# ioam3358 register map
Registers are 32-bit, access not given, no defined reset value unless marked. A register's access mark holds for its fields unless they carry their own. Addresses are absolute; registers are grouped by the start of their names; [hi:lo] are bit positions; {n}, {i} and the like mark numbered series.

## SPINLOCK
0x480CA000 SPINLOCK_REV
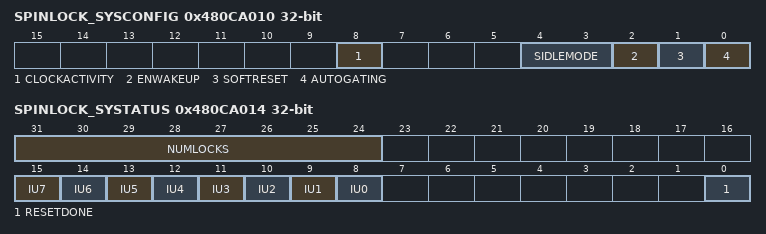
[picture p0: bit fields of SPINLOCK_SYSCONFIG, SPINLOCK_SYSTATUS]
0x480CA010 SPINLOCK_SYSCONFIG
  [8] CLOCKACTIVITY, [4:3] SIDLEMODE, [2] ENWAKEUP, [1] SOFTRESET, [0] AUTOGATING
0x480CA014 SPINLOCK_SYSTATUS
  [31:24] NUMLOCKS, [n+8] IU{n} (n=0..7), [0] RESETDONE
{0x480CA800+4i} SPINLOCK_LOCK_REG_{i} (i=0..31)
  [0] TAKEN

## MMCHS0
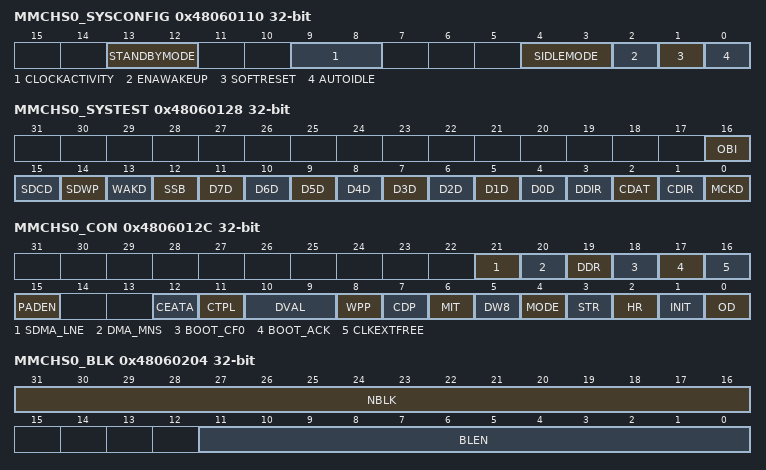
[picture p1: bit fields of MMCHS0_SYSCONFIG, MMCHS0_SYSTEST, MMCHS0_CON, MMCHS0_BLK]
0x48060110 MMCHS0_SYSCONFIG
  [13:12] STANDBYMODE, [9:8] CLOCKACTIVITY, [4:3] SIDLEMODE, [2] ENAWAKEUP, [1] SOFTRESET, [0] AUTOIDLE
0x48060114 MMCHS0_SYSSTATUS
  [0] RESETDONE
0x48060124 MMCHS0_CSRE
0x48060128 MMCHS0_SYSTEST
  [16] OBI, [15] SDCD, [14] SDWP, [13] WAKD, [12] SSB, [n+4] D{n}D (n=0..7), [3] DDIR, [2] CDAT, [1] CDIR, [0] MCKD
0x4806012C MMCHS0_CON
  [21] SDMA_LNE, [20] DMA_MNS, [19] DDR, [18] BOOT_CF0, [17] BOOT_ACK, [16] CLKEXTFREE, [15] PADEN, [12] CEATA, [11] CTPL, [10:9] DVAL, [8] WPP, [7] CDP, [6] MIT, [5] DW8, [4] MODE, [3] STR, [2] HR, [1] INIT, [0] OD
0x48060130 MMCHS0_PWCNT
  [15:0] PWRCNT
0x48060200 MMCHS0_SDMASA
0x48060204 MMCHS0_BLK
  [31:16] NBLK, [11:0] BLEN
0x48060208 MMCHS0_ARG
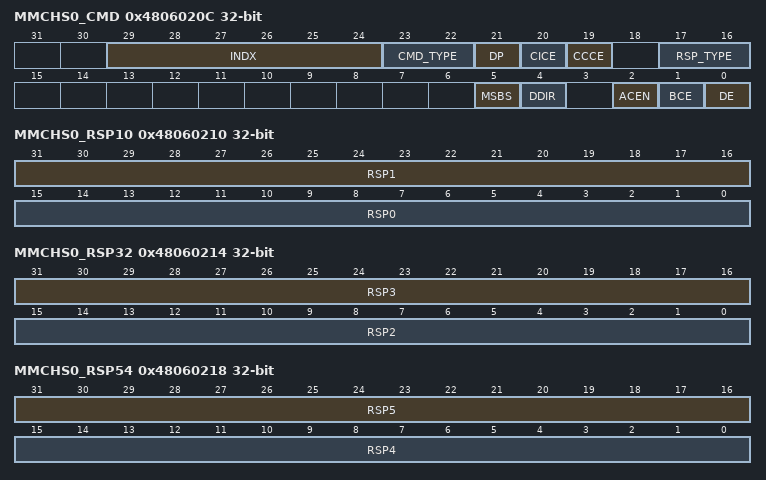
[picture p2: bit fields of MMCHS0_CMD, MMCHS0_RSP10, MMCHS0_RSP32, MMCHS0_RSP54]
0x4806020C MMCHS0_CMD
  [29:24] INDX, [23:22] CMD_TYPE, [21] DP, [20] CICE, [19] CCCE, [17:16] RSP_TYPE, [5] MSBS, [4] DDIR, [2] ACEN, [1] BCE, [0] DE
0x48060210 MMCHS0_RSP10
  [31:16] RSP1, [15:0] RSP0
0x48060214 MMCHS0_RSP32
  [31:16] RSP3, [15:0] RSP2
0x48060218 MMCHS0_RSP54
  [31:16] RSP5, [15:0] RSP4
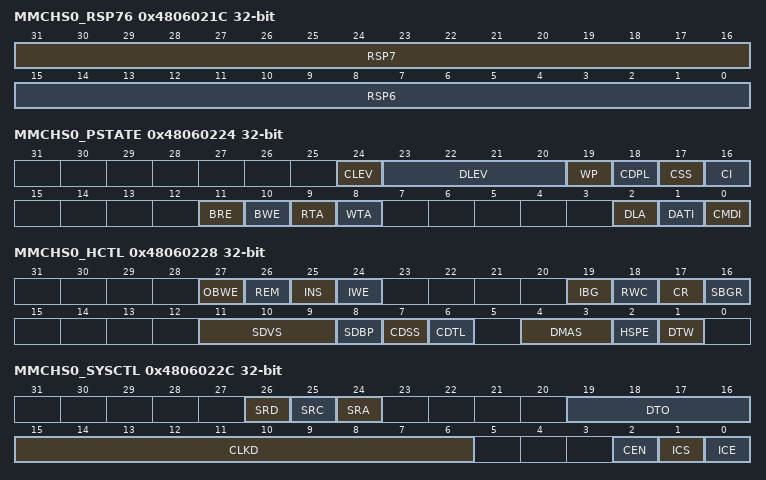
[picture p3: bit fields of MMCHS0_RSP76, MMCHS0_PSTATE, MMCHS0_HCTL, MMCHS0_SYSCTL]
0x4806021C MMCHS0_RSP76
  [31:16] RSP7, [15:0] RSP6
0x48060220 MMCHS0_DATA
0x48060224 MMCHS0_PSTATE
  [24] CLEV, [23:20] DLEV, [19] WP, [18] CDPL, [17] CSS, [16] CI, [11] BRE, [10] BWE, [9] RTA, [8] WTA, [2] DLA, [1] DATI, [0] CMDI
0x48060228 MMCHS0_HCTL
  [27] OBWE, [26] REM, [25] INS, [24] IWE, [19] IBG, [18] RWC, [17] CR, [16] SBGR, [11:9] SDVS, [8] SDBP, [7] CDSS, [6] CDTL, [4:3] DMAS, [2] HSPE, [1] DTW
0x4806022C MMCHS0_SYSCTL
  [26] SRD, [25] SRC, [24] SRA, [19:16] DTO, [15:6] CLKD, [2] CEN, [1] ICS, [0] ICE
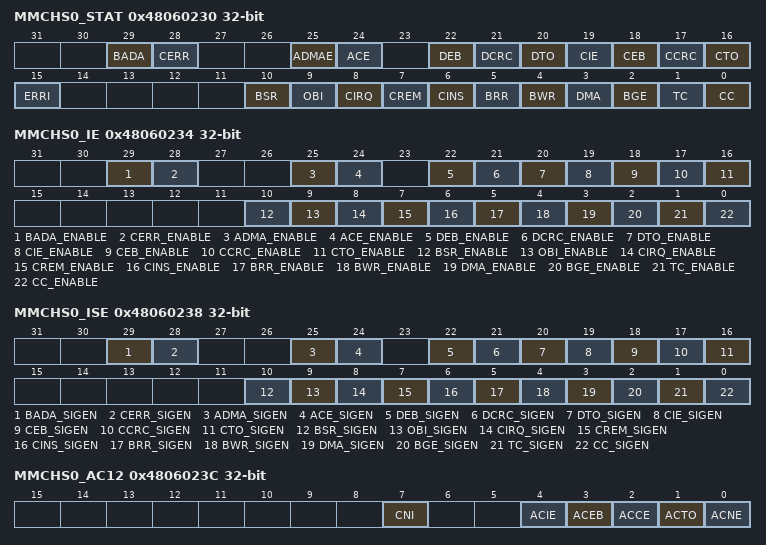
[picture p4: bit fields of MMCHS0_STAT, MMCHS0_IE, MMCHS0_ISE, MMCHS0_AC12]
0x48060230 MMCHS0_STAT
  [29] BADA, [28] CERR, [25] ADMAE, [24] ACE, [22] DEB, [21] DCRC, [20] DTO, [19] CIE, [18] CEB, [17] CCRC, [16] CTO, [15] ERRI, [10] BSR, [9] OBI, [8] CIRQ, [7] CREM, [6] CINS, [5] BRR, [4] BWR, [3] DMA, [2] BGE, [1] TC, [0] CC
0x48060234 MMCHS0_IE
  [29] BADA_ENABLE, [28] CERR_ENABLE, [25] ADMA_ENABLE, [24] ACE_ENABLE, [22] DEB_ENABLE, [21] DCRC_ENABLE, [20] DTO_ENABLE, [19] CIE_ENABLE, [18] CEB_ENABLE, [17] CCRC_ENABLE, [16] CTO_ENABLE, [10] BSR_ENABLE, [9] OBI_ENABLE, [8] CIRQ_ENABLE, [7] CREM_ENABLE, [6] CINS_ENABLE, [5] BRR_ENABLE, [4] BWR_ENABLE, [3] DMA_ENABLE, [2] BGE_ENABLE, [1] TC_ENABLE, [0] CC_ENABLE
0x48060238 MMCHS0_ISE
  [29] BADA_SIGEN, [28] CERR_SIGEN, [25] ADMA_SIGEN, [24] ACE_SIGEN, [22] DEB_SIGEN, [21] DCRC_SIGEN, [20] DTO_SIGEN, [19] CIE_SIGEN, [18] CEB_SIGEN, [17] CCRC_SIGEN, [16] CTO_SIGEN, [10] BSR_SIGEN, [9] OBI_SIGEN, [8] CIRQ_SIGEN, [7] CREM_SIGEN, [6] CINS_SIGEN, [5] BRR_SIGEN, [4] BWR_SIGEN, [3] DMA_SIGEN, [2] BGE_SIGEN, [1] TC_SIGEN, [0] CC_SIGEN
0x4806023C MMCHS0_AC12
  [7] CNI, [4] ACIE, [3] ACEB, [2] ACCE, [1] ACTO, [0] ACNE
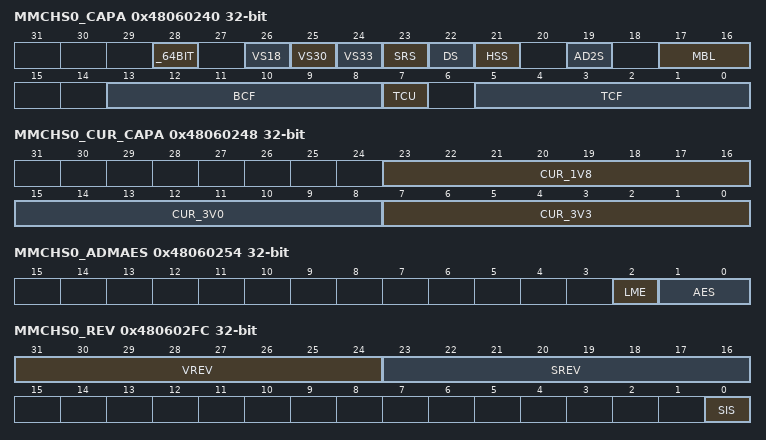
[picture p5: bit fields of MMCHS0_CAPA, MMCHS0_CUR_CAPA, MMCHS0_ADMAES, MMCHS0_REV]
0x48060240 MMCHS0_CAPA
  [28] _64BIT, [26] VS18, [25] VS30, [24] VS33, [23] SRS, [22] DS, [21] HSS, [19] AD2S, [17:16] MBL, [13:8] BCF, [7] TCU, [5:0] TCF
0x48060248 MMCHS0_CUR_CAPA
  [23:16] CUR_1V8, [15:8] CUR_3V0, [7:0] CUR_3V3
0x48060250 MMCHS0_FE
0x48060254 MMCHS0_ADMAES
  [2] LME, [1:0] AES
0x48060258 MMCHS0_ADMASAL
0x4806025C MMCHS0_ADMASAH
0x480602FC MMCHS0_REV
  [31:24] VREV, [23:16] SREV, [0] SIS

## MMCHS1
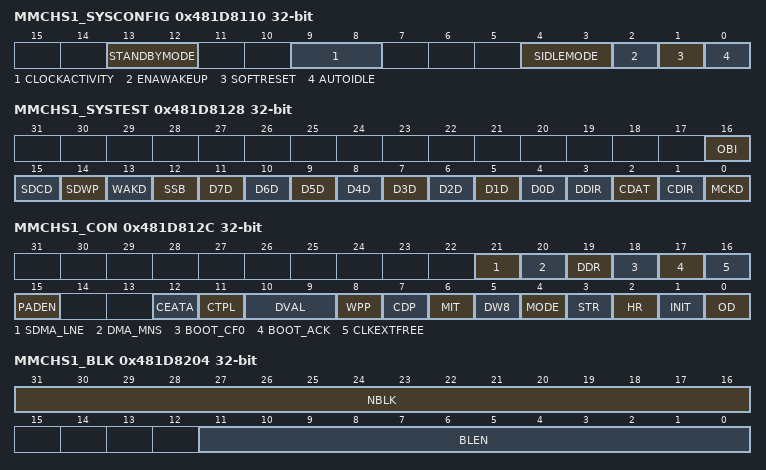
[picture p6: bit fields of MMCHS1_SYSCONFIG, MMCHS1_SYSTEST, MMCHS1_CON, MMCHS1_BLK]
0x481D8110 MMCHS1_SYSCONFIG
  [13:12] STANDBYMODE, [9:8] CLOCKACTIVITY, [4:3] SIDLEMODE, [2] ENAWAKEUP, [1] SOFTRESET, [0] AUTOIDLE
0x481D8114 MMCHS1_SYSSTATUS
  [0] RESETDONE
0x481D8124 MMCHS1_CSRE
0x481D8128 MMCHS1_SYSTEST
  [16] OBI, [15] SDCD, [14] SDWP, [13] WAKD, [12] SSB, [n+4] D{n}D (n=0..7), [3] DDIR, [2] CDAT, [1] CDIR, [0] MCKD
0x481D812C MMCHS1_CON
  [21] SDMA_LNE, [20] DMA_MNS, [19] DDR, [18] BOOT_CF0, [17] BOOT_ACK, [16] CLKEXTFREE, [15] PADEN, [12] CEATA, [11] CTPL, [10:9] DVAL, [8] WPP, [7] CDP, [6] MIT, [5] DW8, [4] MODE, [3] STR, [2] HR, [1] INIT, [0] OD
0x481D8130 MMCHS1_PWCNT
  [15:0] PWRCNT
0x481D8200 MMCHS1_SDMASA
0x481D8204 MMCHS1_BLK
  [31:16] NBLK, [11:0] BLEN
0x481D8208 MMCHS1_ARG
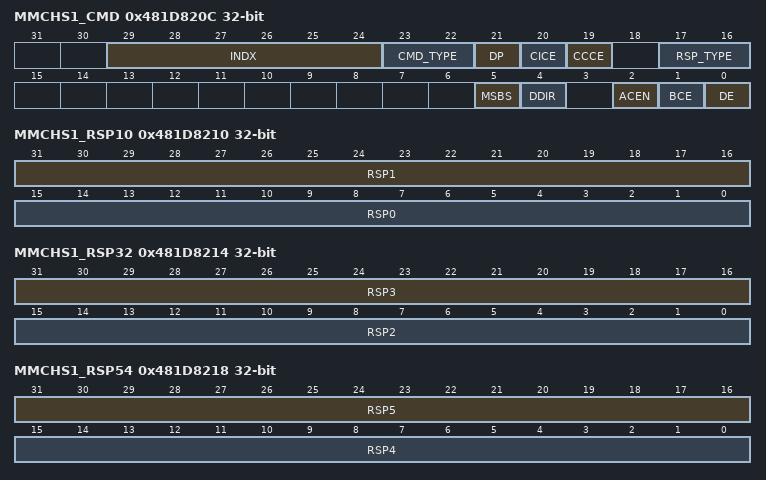
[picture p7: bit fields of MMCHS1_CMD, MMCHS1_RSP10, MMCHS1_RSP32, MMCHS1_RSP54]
0x481D820C MMCHS1_CMD
  [29:24] INDX, [23:22] CMD_TYPE, [21] DP, [20] CICE, [19] CCCE, [17:16] RSP_TYPE, [5] MSBS, [4] DDIR, [2] ACEN, [1] BCE, [0] DE
0x481D8210 MMCHS1_RSP10
  [31:16] RSP1, [15:0] RSP0
0x481D8214 MMCHS1_RSP32
  [31:16] RSP3, [15:0] RSP2
0x481D8218 MMCHS1_RSP54
  [31:16] RSP5, [15:0] RSP4
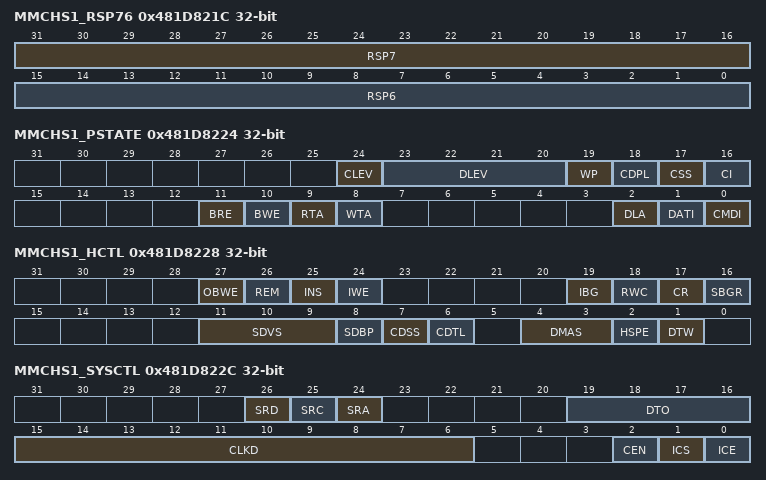
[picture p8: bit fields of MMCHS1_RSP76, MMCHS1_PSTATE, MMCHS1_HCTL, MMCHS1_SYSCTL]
0x481D821C MMCHS1_RSP76
  [31:16] RSP7, [15:0] RSP6
0x481D8220 MMCHS1_DATA
0x481D8224 MMCHS1_PSTATE
  [24] CLEV, [23:20] DLEV, [19] WP, [18] CDPL, [17] CSS, [16] CI, [11] BRE, [10] BWE, [9] RTA, [8] WTA, [2] DLA, [1] DATI, [0] CMDI
0x481D8228 MMCHS1_HCTL
  [27] OBWE, [26] REM, [25] INS, [24] IWE, [19] IBG, [18] RWC, [17] CR, [16] SBGR, [11:9] SDVS, [8] SDBP, [7] CDSS, [6] CDTL, [4:3] DMAS, [2] HSPE, [1] DTW
0x481D822C MMCHS1_SYSCTL
  [26] SRD, [25] SRC, [24] SRA, [19:16] DTO, [15:6] CLKD, [2] CEN, [1] ICS, [0] ICE
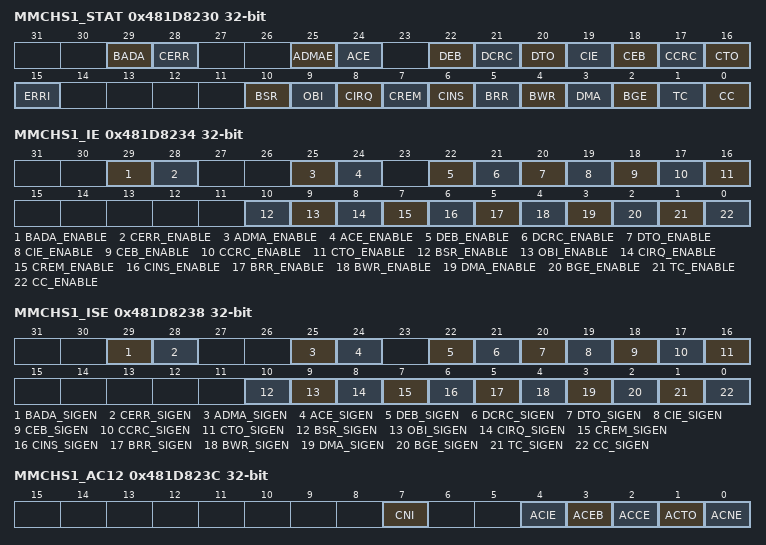
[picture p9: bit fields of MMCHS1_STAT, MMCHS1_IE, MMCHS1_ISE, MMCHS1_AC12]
0x481D8230 MMCHS1_STAT
  [29] BADA, [28] CERR, [25] ADMAE, [24] ACE, [22] DEB, [21] DCRC, [20] DTO, [19] CIE, [18] CEB, [17] CCRC, [16] CTO, [15] ERRI, [10] BSR, [9] OBI, [8] CIRQ, [7] CREM, [6] CINS, [5] BRR, [4] BWR, [3] DMA, [2] BGE, [1] TC, [0] CC
0x481D8234 MMCHS1_IE
  [29] BADA_ENABLE, [28] CERR_ENABLE, [25] ADMA_ENABLE, [24] ACE_ENABLE, [22] DEB_ENABLE, [21] DCRC_ENABLE, [20] DTO_ENABLE, [19] CIE_ENABLE, [18] CEB_ENABLE, [17] CCRC_ENABLE, [16] CTO_ENABLE, [10] BSR_ENABLE, [9] OBI_ENABLE, [8] CIRQ_ENABLE, [7] CREM_ENABLE, [6] CINS_ENABLE, [5] BRR_ENABLE, [4] BWR_ENABLE, [3] DMA_ENABLE, [2] BGE_ENABLE, [1] TC_ENABLE, [0] CC_ENABLE
0x481D8238 MMCHS1_ISE
  [29] BADA_SIGEN, [28] CERR_SIGEN, [25] ADMA_SIGEN, [24] ACE_SIGEN, [22] DEB_SIGEN, [21] DCRC_SIGEN, [20] DTO_SIGEN, [19] CIE_SIGEN, [18] CEB_SIGEN, [17] CCRC_SIGEN, [16] CTO_SIGEN, [10] BSR_SIGEN, [9] OBI_SIGEN, [8] CIRQ_SIGEN, [7] CREM_SIGEN, [6] CINS_SIGEN, [5] BRR_SIGEN, [4] BWR_SIGEN, [3] DMA_SIGEN, [2] BGE_SIGEN, [1] TC_SIGEN, [0] CC_SIGEN
0x481D823C MMCHS1_AC12
  [7] CNI, [4] ACIE, [3] ACEB, [2] ACCE, [1] ACTO, [0] ACNE
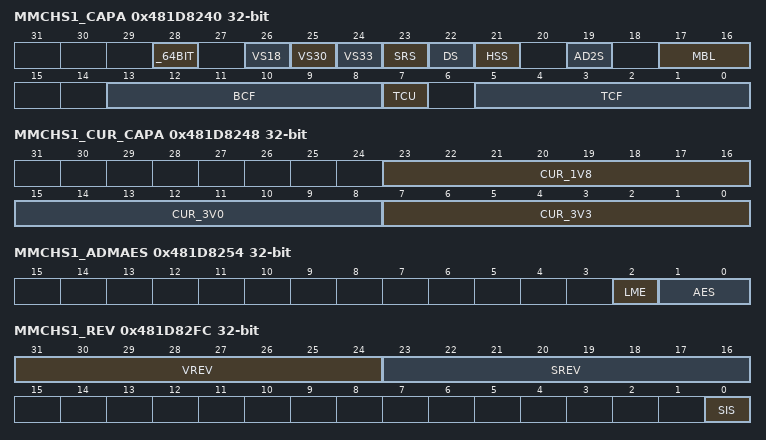
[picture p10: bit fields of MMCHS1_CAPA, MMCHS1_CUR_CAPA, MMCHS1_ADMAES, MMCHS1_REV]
0x481D8240 MMCHS1_CAPA
  [28] _64BIT, [26] VS18, [25] VS30, [24] VS33, [23] SRS, [22] DS, [21] HSS, [19] AD2S, [17:16] MBL, [13:8] BCF, [7] TCU, [5:0] TCF
0x481D8248 MMCHS1_CUR_CAPA
  [23:16] CUR_1V8, [15:8] CUR_3V0, [7:0] CUR_3V3
0x481D8250 MMCHS1_FE
0x481D8254 MMCHS1_ADMAES
  [2] LME, [1:0] AES
0x481D8258 MMCHS1_ADMASAL
0x481D825C MMCHS1_ADMASAH
0x481D82FC MMCHS1_REV
  [31:24] VREV, [23:16] SREV, [0] SIS
